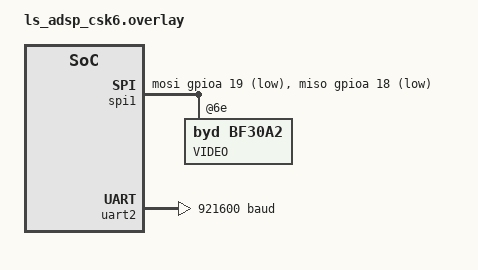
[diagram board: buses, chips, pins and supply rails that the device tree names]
&spi1 {
        miso-gpios = <&gpioa 18 7>;
        mosi-gpios = <&gpioa 19 7>;
        sclk-gpios = <&gpioa 20 7>;
        cs-gpios   = <&gpioa 17 7>;

        status = "okay";
        spi-max-frequency = <25000000>;

        bf30a2: bf30a2@6e {
            compatible = "byd,bf30a2";
            status = "okay";
            label = "VIDEO";
            reg = <0x6e>;
            csk6-spec;
    };
};

&uart2 {
	current-speed = <921600>;
	pinmuxs = <&pinmuxb 7 3>, <&pinmuxb 6 3>;
    /* pinmux-names = "RXD", "TXD"; */
	status = "okay";
};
